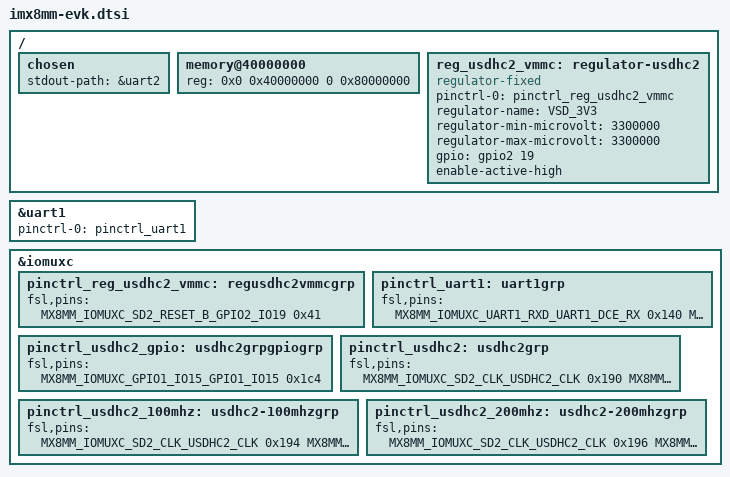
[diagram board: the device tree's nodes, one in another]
// SPDX-License-Identifier: (GPL-2.0+ OR MIT)
/*
 * Copyright 2020 NXP
 */

/dts-v1/;

#include <dt-bindings/usb/pd.h>
#include "imx8mm.dtsi"

/ {
	chosen {
		stdout-path = &uart2;
	};

	memory@40000000 {
		device_type = "memory";
		reg = <0x0 0x40000000 0 0x80000000>;
	};

	reg_usdhc2_vmmc: regulator-usdhc2 {
		compatible = "regulator-fixed";
		pinctrl-names = "default";
		pinctrl-0 = <&pinctrl_reg_usdhc2_vmmc>;
		regulator-name = "VSD_3V3";
		regulator-min-microvolt = <3300000>;
		regulator-max-microvolt = <3300000>;
		gpio = <&gpio2 19 GPIO_ACTIVE_HIGH>;
		enable-active-high;
	};
};

&uart1 { /* console */
	pinctrl-names = "default";
	pinctrl-0 = <&pinctrl_uart1>;
	status = "okay";
};

&iomuxc {
	pinctrl_reg_usdhc2_vmmc: regusdhc2vmmcgrp {
		fsl,pins = <
			MX8MM_IOMUXC_SD2_RESET_B_GPIO2_IO19	0x41
		>;
	};

	pinctrl_uart1: uart1grp {
		fsl,pins = <
			MX8MM_IOMUXC_UART1_RXD_UART1_DCE_RX		0x140
			MX8MM_IOMUXC_UART1_TXD_UART1_DCE_TX		0x140
		>;
	};

	pinctrl_usdhc2_gpio: usdhc2grpgpiogrp {
		fsl,pins = <
			MX8MM_IOMUXC_GPIO1_IO15_GPIO1_IO15	0x1c4
		>;
	};

	pinctrl_usdhc2: usdhc2grp {
		fsl,pins = <
			MX8MM_IOMUXC_SD2_CLK_USDHC2_CLK		0x190
			MX8MM_IOMUXC_SD2_CMD_USDHC2_CMD		0x1d0
			MX8MM_IOMUXC_SD2_DATA0_USDHC2_DATA0	0x1d0
			MX8MM_IOMUXC_SD2_DATA1_USDHC2_DATA1	0x1d0
			MX8MM_IOMUXC_SD2_DATA2_USDHC2_DATA2	0x1d0
			MX8MM_IOMUXC_SD2_DATA3_USDHC2_DATA3	0x1d0
			MX8MM_IOMUXC_GPIO1_IO04_USDHC2_VSELECT	0x1d0
		>;
	};

	pinctrl_usdhc2_100mhz: usdhc2-100mhzgrp {
		fsl,pins = <
			MX8MM_IOMUXC_SD2_CLK_USDHC2_CLK		0x194
			MX8MM_IOMUXC_SD2_CMD_USDHC2_CMD		0x1d4
			MX8MM_IOMUXC_SD2_DATA0_USDHC2_DATA0	0x1d4
			MX8MM_IOMUXC_SD2_DATA1_USDHC2_DATA1	0x1d4
			MX8MM_IOMUXC_SD2_DATA2_USDHC2_DATA2	0x1d4
			MX8MM_IOMUXC_SD2_DATA3_USDHC2_DATA3	0x1d4
			MX8MM_IOMUXC_GPIO1_IO04_USDHC2_VSELECT	0x1d0
		>;
	};

	pinctrl_usdhc2_200mhz: usdhc2-200mhzgrp {
		fsl,pins = <
			MX8MM_IOMUXC_SD2_CLK_USDHC2_CLK		0x196
			MX8MM_IOMUXC_SD2_CMD_USDHC2_CMD		0x1d6
			MX8MM_IOMUXC_SD2_DATA0_USDHC2_DATA0	0x1d6
			MX8MM_IOMUXC_SD2_DATA1_USDHC2_DATA1	0x1d6
			MX8MM_IOMUXC_SD2_DATA2_USDHC2_DATA2	0x1d6
			MX8MM_IOMUXC_SD2_DATA3_USDHC2_DATA3	0x1d6
			MX8MM_IOMUXC_GPIO1_IO04_USDHC2_VSELECT	0x1d0
		>;
	};
};
